# PIC32CX1025SG41100 device description
Architecture: CORTEX-M4; Family: PIC32CX; Series: PIC32CXSG41
Registers are 32-bit, read-write, reset 0x0 unless marked. A register's access mark holds for its fields unless they carry their own. Offsets are from the block's base; [hi:lo] are bit positions; lines under a group give offsets from that group; {n}, {i} and the like mark numbered series; 'fields as' and 'values as' point back to an identical list.

## PCC — Parallel Capture Controller
Instances: PCC 0x43002C00
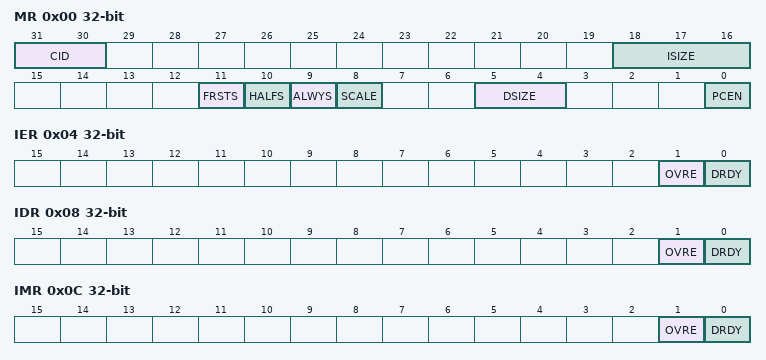
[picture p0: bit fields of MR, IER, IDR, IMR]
0x00 MR — Mode Register
  [31:30] CID — Clear If Disabled
  [18:16] ISIZE — Input Data Size
    0=8BITS (Input data bus size is 8 bits); 1=10BITS (Input data bus size is 10 bits); 2=12BITS (Input data bus size is 12 bits); 3=14BITS (Input data bus size is 14 bits)
  [11] FRSTS — First sample
  [10] HALFS — Half Sampling
  [9] ALWYS — Always Sampling
  [8] SCALE — Scale data
  [5:4] DSIZE — Data size
    0=1DATA (1 data is read in the PCC_RHR); 1=2DATA (2 data is read in the PCC_RHR); 2=4DATA (4 data are read in the PCC_RHR (only for 8 bits data size, ISIZE = 0))
  [0] PCEN — Parallel Capture Enable
0x04 IER wo (atomic set of IMR) — Interrupt Enable Register
  [1] OVRE — Overrun Error Interrupt Enable
  [0] DRDY — Data Ready Interrupt Enable
0x08 IDR wo (atomic clear of IMR) — Interrupt Disable Register
  [1] OVRE — Overrun Error Interrupt Disable
  [0] DRDY — Data Ready Interrupt Disable
0x0C IMR ro — Interrupt Mask Register
  [1] OVRE — Overrun Error Interrupt Mask
  [0] DRDY — Data Ready Interrupt Mask
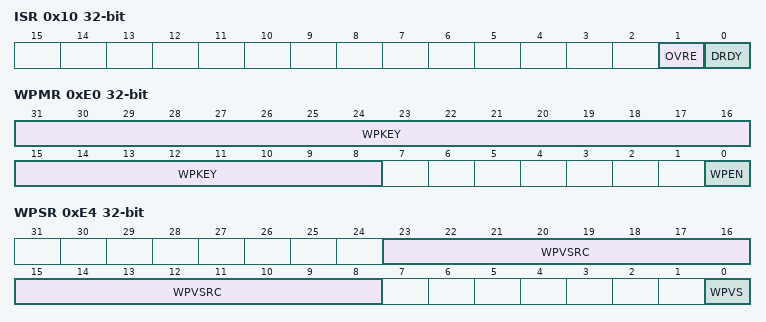
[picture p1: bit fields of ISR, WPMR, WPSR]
0x10 ISR ro — Interrupt Status Register
  [1] OVRE — Overrun Error Interrupt Status
  [0] DRDY — Data Ready Interrupt Status
0x14 RHR ro — Reception Holding Register
  [31:0] RDATA — Reception Data
0xE0 WPMR — Write Protection Mode Register
  [31:8] WPKEY — Write Protection Key
    0x504343=PASSWD (Write Protection Key)
  [0] WPEN — Write Protection Enable
0xE4 WPSR ro — Write Protection Status Register
  [23:8] WPVSRC — Write Protection Violation Status
  [0] WPVS — Write Protection Violation Source

## PM — Power Manager
Instances: PM 0x40000400
0x00 CTRLA 8-bit — Control A
  [2] IORET — I/O Retention
0x01 SLEEPCFG 8-bit reset 0x2 — Sleep Configuration
  [2:0] SLEEPMODE
    2=IDLE (CPU, AHBx, and APBx clocks are OFF); 4=STANDBY (All Clocks are OFF); 5=HIBERNATE (Backup domain is ON as well as some PDRAMs); 6=BACKUP (Only Backup domain is powered ON); 7=OFF (All power domains are powered OFF)
0x04 INTENCLR 8-bit (atomic clear) — Interrupt Enable Clear
  [0] SLEEPRDY — Sleep Mode Entry Ready Enable
0x05 INTENSET 8-bit (atomic set) — Interrupt Enable Set
  [0] SLEEPRDY — Sleep Mode Entry Ready Enable
0x06 INTFLAG 8-bit (atomic clear) — Interrupt Flag Status and Clear
  [0] SLEEPRDY — Sleep Mode Entry Ready
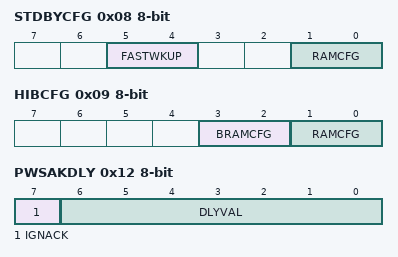
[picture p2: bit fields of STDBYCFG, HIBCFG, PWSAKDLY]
0x08 STDBYCFG 8-bit — Standby Configuration
  [5:4] FASTWKUP — Fast Wakeup
    0=NO (Fast Wakeup is disabled); 1=NVM (Fast Wakeup is enabled on NVM); 2=MAINVREG (Fast Wakeup is enabled on the main voltage regulator (MAINVREG)); 3=BOTH (Fast Wakeup is enabled on both NVM and MAINVREG)
  [1:0] RAMCFG — Ram Configuration
    0=RET (All the system RAM is retained); 1=PARTIAL (Only the first 32Kbytes of the system RAM is retained); 2=OFF (All the system RAM is turned OFF)
0x09 HIBCFG 8-bit — Hibernate Configuration
  [3:2] BRAMCFG — Backup Ram Configuration
    0=RET (All the backup RAM is retained); 1=PARTIAL (Only the first 4Kbytes of the backup RAM is retained); 2=OFF (All the backup RAM is turned OFF)
  [1:0] RAMCFG — Ram Configuration
    values as STDBYCFG.RAMCFG
0x0A BKUPCFG 8-bit — Backup Configuration
  [1:0] BRAMCFG — Ram Configuration
    values as HIBCFG.BRAMCFG
0x12 PWSAKDLY 8-bit — Power Switch Acknowledge Delay
  [7] IGNACK — Ignore Acknowledge
  [6:0] DLYVAL — Delay Value

## PORT — Port Module
Instances: PORT 0x41008000
{0x0+0x80*i} GROUP[{i}] (i=0..3) group
  0x00 DIR — Data Direction
    [31:0] DIR — Port Data Direction
  0x04 DIRCLR (atomic clear of DIR) — Data Direction Clear
    [31:0] DIRCLR — Port Data Direction Clear
  0x08 DIRSET (atomic set of DIR) — Data Direction Set
    [31:0] DIRSET — Port Data Direction Set
  0x0C DIRTGL (atomic toggle of DIR) — Data Direction Toggle
    [31:0] DIRTGL — Port Data Direction Toggle
  0x10 OUT — Data Output Value
    [31:0] OUT — PORT Data Output Value
  0x14 OUTCLR (atomic clear of OUT) — Data Output Value Clear
    [31:0] OUTCLR — PORT Data Output Value Clear
  0x18 OUTSET (atomic set of OUT) — Data Output Value Set
    [31:0] OUTSET — PORT Data Output Value Set
  0x1C OUTTGL (atomic toggle of OUT) — Data Output Value Toggle
    [31:0] OUTTGL — PORT Data Output Value Toggle
  0x20 IN ro — Data Input Value
    [31:0] IN — PORT Data Input Value
  0x24 CTRL — Control
    [31:0] SAMPLING — Input Sampling Mode
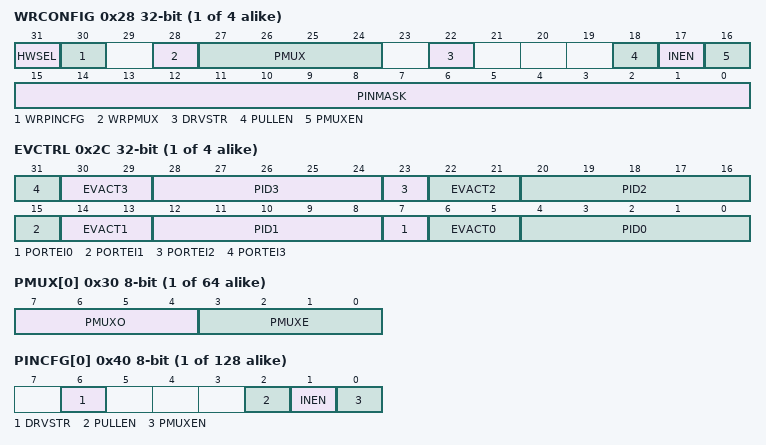
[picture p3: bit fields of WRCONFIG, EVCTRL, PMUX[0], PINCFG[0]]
  0x28 WRCONFIG wo — Write Configuration
    [31] HWSEL — Half-Word Select
    [30] WRPINCFG — Write PINCFG
    [28] WRPMUX — Write PMUX
    [27:24] PMUX — Peripheral Multiplexing
    [22] DRVSTR — Output Driver Strength Selection
    [18] PULLEN — Pull Enable
    [17] INEN — Input Enable
    [16] PMUXEN — Peripheral Multiplexer Enable
    [15:0] PINMASK — Pin Mask for Multiple Pin Configuration
  0x2C EVCTRL — Event Input Control
    [8n+7] PORTEI{n} (n=0..3) — PORT Event Input Enable {n}
    [30:29] EVACT3 — PORT Event Action 3
    [8n+4:8n] PID{n} (n=0..3) — PORT Event Pin Identifier {n}
    [22:21] EVACT2 — PORT Event Action 2
    [14:13] EVACT1 — PORT Event Action 1
    [6:5] EVACT0 — PORT Event Action 0
      0=OUT (Event output to pin); 1=SET (Set output register of pin on event); 2=CLR (Clear output register of pin on event); 3=TGL (Toggle output register of pin on event)
  {0x30+j} PMUX[{j}] (j=0..15) 8-bit — Peripheral Multiplexing
    [7:4] PMUXO — Peripheral Multiplexing for Odd-Numbered Pin
      0=A (Peripheral function A selected); 1=B (Peripheral function B selected); 2=C (Peripheral function C selected); 3=D (Peripheral function D selected); 4=E (Peripheral function E selected); 5=F (Peripheral function F selected); 6=G (Peripheral function G selected); 7=H (Peripheral function H selected); 8=I (Peripheral function I selected); 9=J (Peripheral function J selected); 10=K (Peripheral function K selected); 11=L (Peripheral function L selected); 12=M (Peripheral function M selected); 13=N (Peripheral function N selected)
    [3:0] PMUXE — Peripheral Multiplexing for Even-Numbered Pin
      values as PMUXO
  {0x40+j} PINCFG[{j}] (j=0..31) 8-bit — Pin Configuration
    [6] DRVSTR — Output Driver Strength Selection
    [2] PULLEN — Pull Enable
    [1] INEN — Input Enable
    [0] PMUXEN — Peripheral Multiplexer Enable
